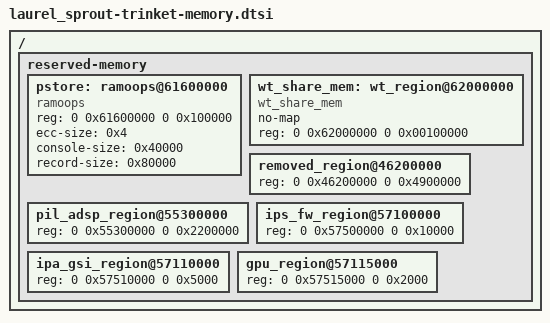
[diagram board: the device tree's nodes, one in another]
/ {
	/delete-node/ mem-offline;

	reserved-memory {
		pstore: ramoops@61600000 {
			compatible = "ramoops";
			reg = <0 0x61600000 0 0x100000>;
			ecc-size		= <0x4>;
			console-size	= <0x40000>;
			record-size = <0x80000>;
		};
		wt_share_mem: wt_region@62000000 {
			compatible = "wt_share_mem";
			no-map;
			reg = <0 0x62000000 0 0x00100000>;
		};

		removed_region@46200000 {
			reg = <0 0x46200000 0 0x4900000>;
		};

		pil_adsp_region@55300000 {
			reg = <0 0x55300000 0 0x2200000>;
		};

		ips_fw_region@57100000 {
			reg = <0 0x57500000 0 0x10000>;
		};

		ipa_gsi_region@57110000 {
			reg = <0 0x57510000 0 0x5000>;
		};

		gpu_region@57115000 {
			reg = <0 0x57515000 0 0x2000>;
		};
	};
};
